# STM32MP21_CM33 register map
File version: 0.4
CPU: CM33 r0p1, little endian, MPU, FPU, vendor SysTick, 8 interrupt priority bits
Registers are 32-bit, read-write, reset 0x0 unless marked. A register's access mark holds for its fields unless they carry their own. Offsets are from the block's base; [hi:lo] are bit positions; {n}, {i} and the like mark numbered series; 'fields as' and 'values as' point back to an identical list.

## FMC (part 2 of 2) — FMC address block description
Base 0x48200000
Same registers: FMC_S 0x58200000
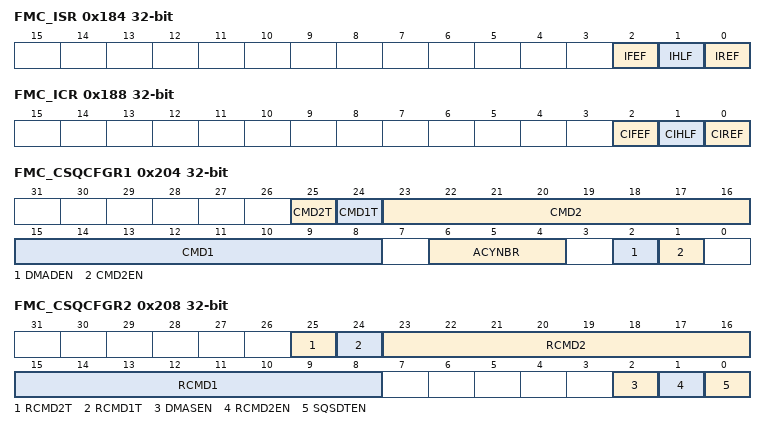
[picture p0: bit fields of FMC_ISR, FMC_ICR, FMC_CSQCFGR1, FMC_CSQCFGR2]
0x184 FMC_ISR ro — FMC interrupt status register
  [2] IFEF — Interrupt falling edge flag The flag is set by hardware and cleared by setting the CFEIF bit.
    0=No interrupt falling edge occurred; 1=Interrupt falling edge occurred
  [1] IHLF — Interrupt high-level flag The flag is set by hardware and cleared by setting the CHLIF bit.
    0=No Interrupt high-level occurred; 1=Interrupt high-level occurred
  [0] IREF — Interrupt rising edge flag The flag is set by hardware and cleared by setting the CREIF bit.
    0=No interrupt rising edge occurred; 1=Interrupt rising edge occurred
0x188 FMC_ICR wo — FMC NAND controller interrupt clear register
  [2] CIFEF — Clear Interrupt falling edge flag
    0=No effect; 1=Clears the IFEF flag in the FMC_ISR register
  [1] CIHLF — Clear Interrupt high-level flag
    0=No effect; 1=Clears the IHLF flag in the FMC_ISR register
  [0] CIREF — Clear Interrupt rising edge flag
    0=No effect; 1=Clear the IREF flag in the FMC_ISR register
0x200 FMC_CSQCR wo — FMC NAND command sequencer control register
  [0] CSQSTART — Command Sequencer Enable Writing 1 starts the Command sequencer. Writing 0 has no effect. Note: Write this bit to 1 to start the sequencer only when the FMC is enabled by setting FMCEN bit of FMC_CFGR to 1 and the NAND flash controller is activated by setting PBKEN bit of FMC_PCR to 1.
0x204 FMC_CSQCFGR1 — FMC NAND command sequencer configuration register 1
  [25] CMD2T — Command 2 Sequencer timings This bit specifies if the Command 2 (CMD2) is issued to the NAND flash memory with the timings defined in FMC_PMEM or FMC_PATT register.
    0=CMD2 issued with the timings programmed in FMC_PMEM; 1=CMD2 issued with the timings programmed in FMC_PATT
  [24] CMD1T — Command 1 Sequencer timings This bit specifies if the Command 1 (CMD1) is issued to the NAND flash memory with the timings programmed in FMC_PMEM or FMC_PATT register.
    0=CMD1 issued with the timings programmed in FMC_PMEM; 1=CMD1 issued with the timings programmed in FMC_PATT
  [23:16] CMD2 — Command 2 sequencer These bits specify if the Command 2 is issued by the command sequencer for the command second cycle during read operations.This command is only issued when the CMD2EN bit is set. Example: CMD2[7:0] bits must be programmed to 0x30 to issue the read column command.
  [15:8] CMD1 — Command 1 sequencer These bits specify if the Command 1 is issued by the command sequencer for the first cycle during read or write operations.
  [6:4] ACYNBR — Address Cycle number These bits define the number of address cycles to be generated by the command sequencer when issuing the command programmed in the registers. Others: Reserved.
    0=No address cycle; 1=1 address cycle; {v}={v} address cycles (v=2..5)
  [2] DMADEN — Command sequencer DMA request data enable When this bit is set, the command sequencer generates a DMA request to the first DMA channel, to transfer data from/to NAND flash memory.
    0=No DMA request transfer; 1=A DMA request transfer
  [1] CMD2EN — Command cycle 2 Enable This bit specifies that the command cycle 2 has to be generated by the command sequencer.
    0=Command cycle 2 not issued; 1=Command cycle 2 (programmed CMD2[7:0]) sent by the command sequencer to the NAND flash memory after the address cycles
0x208 FMC_CSQCFGR2 — FMC NAND command sequencer configuration register 2
  [25] RCMD2T — Command 1 sequencer timings This bit specifies if the CMD1 is issued to the NAND flash memory with the timings programmed in FMC_PMEM or FMC_PATT register.
    values as FMC_CSQCFGR1.CMD1T
  [24] RCMD1T — Command 1 sequencer timings This bit specifies if the CMD1 is issued to the NAND flash memory with the timings flash memory in FMC_PMEM or FMC_PATT register.
    values as FMC_CSQCFGR1.CMD1T
  [23:16] RCMD2 — Random Command 2 sequencer These bits specify that the command 2 is issued by the command sequencer for the second cycle during read operations.This command is only issued when the RCMD2EN bit is set. Example: the RCMD2 (0xE0) is required to issue the random read column command.
  [15:8] RCMD1 — Random Command 1 sequencer These bits specify that the command 1 value is issued by the command sequencer for the first cycle during read or write accesses.
  [2] DMASEN — Command sequencer DMA request decoding status enable When this bit is set, the command sequencer generates a DMA request to the second DMA channel when valid bits are available in the ECC status register at the end of ECC processing (decoding). Note: This bit must be set only during a page read sequence to offload the saving of the ECC results between sectors by using a second DMA channel.
    0=No DMA request used for ECC status registers transfer; 1=A DMA request used for ECC status registers transfer
  [1] RCMD2EN — Random Command 2 sequencer enable This bit enables the command 2 to be issued by the command sequencer during read accesses. This command is issued only when the CMD2SQEN bit is set.
    0=Command 2 not issued; 1=Command 2 (CMD2SQ[7:0]) issued by the command sequencer to NAND flash memory after the address cycle
  [0] SQSDTEN — Sequencer spare data transfer enable This bit enables the sequencer to access the spare data area after each sector transfer. It also enables the ECC when using the sequencer. ECCEN bit in FMC_PCR register must be reset.
    0=ECC disabled and spare data area not accessed by the sequencer; 1=ECC enabled and spare data area read or programmed by the sequencer after each sector transfer
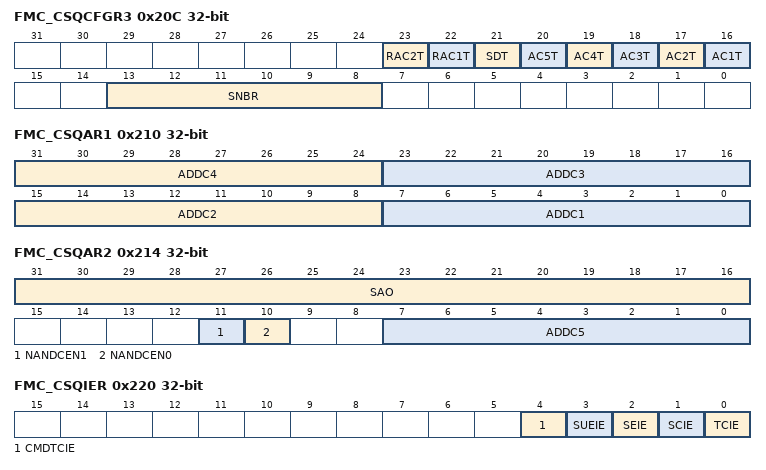
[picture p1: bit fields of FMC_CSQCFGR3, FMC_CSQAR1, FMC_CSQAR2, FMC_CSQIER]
0x20C FMC_CSQCFGR3 — FMC NAND sequencer configuration register 3
  [23] RAC2T — Random Address cycle 2 sequencer timings This bit specifies if the random Address cycle 2 (ADDC2) is issued to the NAND flash memory with the timings programmed in FMC_PMEM or in FMC_PATT register.
    0=Random ADDC2 issued with the timings programmed in FMC_PMEM; 1=Random ADDC2 issued with the timings programmed in FMC_PATT
  [22] RAC1T — Random Address cycle 1 sequencer timings This bit specifies if the random Address cycle 1 (ADDC1) is issued to the NAND flash memory with the timings programmed in FMC_PMEM or in FMC_PATT register.
    0=Random ADDC1 issued with the timings programmed in FMC_PMEM; 1=Random ADDC1 issued with the timings programmed in FMC_PATT
  [21] SDT — Spare data transfer sequencer timings This bit specifies if the spare data transfer for read and write operations from/to the NAND flash memory are performed with the timings programmed in FMC_PMEM or FMC_PATT register.
    0=Spare data transfer issued with the timings programmed in FMC_PMEM; 1=Spare data transfer issued with the timings programmed in FMC_PATT
  [20] AC5T — Address cycle 5 sequencer timings This bit defines if the Address cycle 5(ADDC1) is issued to the NAND flash memory with the timings programmed in FMC_PMEM or FMC_PATT register.
    0=ADDC5 issued with the timings programmed in FMC_PMEM; 1=ADDC5 issued with the timings programmed in FMC_PATT
  [19] AC4T — Address cycle 4sequencer timings This bit defines if the Address cycle 4 (ADDC4) is issued to the NAND flash memory with the timings programmed in FMC_PMEM or FMC_PATT register.
    0=ADDC4 issued with the timings programmed in FMC_PMEM; 1=ADDC4 issued with the timings programmed in FMC_PATT
  [18] AC3T — Address cycle 3 sequencer timings This bit defines if the Address cycle 3 (ADDC3) is issued to the NAND flash memory with the timings programmed in FMC_PMEM or FMC_PATT register.
    0=ADDC3 issued with the timings programmed in FMC_PMEM; 1=ADDC3 issued with the timings programmed in FMC_PATT
  [17] AC2T — Address cycle 2 sequencer timings This bit defines if the Address cycle 2 (ADDC2) is issued to the NAND flash memory with the timings programmed in FMC_PMEM or FMC_PATT register.
    0=ADDC2 issued with the timings programmed in FMC_PMEM; 1=ADDC2 issued with the timings programmed in FMC_PATT
  [16] AC1T — Address cycle 1 sequencer timings This bit defines if the Address cycle 1 (ADDC1) is issued to the NAND flash memory with the timings programmed in FMC_PMEM or FMC_PATT register.
    0=ADDC1 issued with the timings programmed in FMC_PMEM; 1=ADDC1 issued with the timings programmed in FMC_PATT
  [13:8] SNBR — Number of sectors to be read/written These bits define the number of sectors that are processed by the sequencer. They are used to read/write part of a page or to use the ECC (in particular with the BCH code which requires 512-byte sectors): ... Others: Reserved.
    0=1 sector; 1=2 sectors; 63=16 sectors
0x210 FMC_CSQAR1 — FMC NAND command sequencer address register 1
  [31:24] ADDC4 — Address Cycle 4 These bits define the value of address cycle 4 to be issued by the command sequencer during read or write accesses.
  [23:16] ADDC3 — Address Cycle 3 These bits define the value of address cycle 2 to be issued by the command sequencer during read or write accesses.
  [15:8] ADDC2 — Address Cycle 2 These bits define the value of address cycle 2 to be issued by the command sequencer during read or write accesses.
  [7:0] ADDC1 — Address Cycle 1 These bits define the value of address cycle 1 to be issued by the command sequencer during read or write accesses.
0x214 FMC_CSQAR2 — FMC NAND command sequencer address register 2
  [31:16] SAO — Spare Area Address Offset These bits define the offset of the first ECC byte in the spare area for the program sequence. Note: The minimum SAQ value is 2 since the first two bytes of the spare area are reserved for Bad block marking and metadata.
  [11] NANDCEN1 — NAND flash chip enable number These bits define the chip enable to be selected by the NAND flash command sequencer.
    0=NCE1 chip enable selected; 1=NCE2 chip enable selected
  [10] NANDCEN0 — NAND flash chip enable number These bits define the chip enable to be selected by the NAND flash command sequencer.
    0=NCE1 chip enable selected; 1=NCE2 chip enable selected
  [7:0] ADDC5 — Address Cycle 5 These bits define the value of address cycle 5 to be issued by the command sequencer during read or write accesses.
0x220 FMC_CSQIER — FMC NAND command sequencer interrupt enable register
  [4] CMDTCIE — Command Transfer Complete interrupt enable
    0=Command Transfer Complete Interrupt disable; 1=Command Transfer Complete Interrupt enable
  [3] SUEIE — Sector Uncorrectable Error interrupt enable
    values as CMDTCIE
  [2] SEIE — Sector Error interrupt enable
    0=Sector Error Interrupt disable; 1=Sector Error Interrupt enable
  [1] SCIE — Sector Complete interrupt enable
    0=Sector Complete Interrupt disable; 1=Sector Complete Interrupt enable
  [0] TCIE — Transfer Complete Interrupt enable
    0=Transfer Complete Interrupt disable; 1=Transfer Complete Interrupt enable
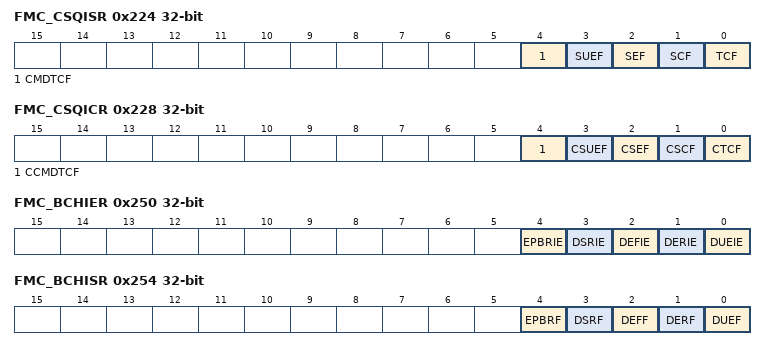
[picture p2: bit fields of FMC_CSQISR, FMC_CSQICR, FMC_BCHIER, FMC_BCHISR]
0x224 FMC_CSQISR — FMC NAND command sequencer interrupt status register
  [4] CMDTCF — Command Transfer Complete flag This bit is set when the command sequencer has completed the transfer of programmed commands and addresses. This bit is cleared by setting CCMDTCF bit. An interrupt can be generated if the CMDTCIE bit is set in the FMC_CSQICR register. Note: The Sector Transfer Complete interrupt is not needed in sequencer mode.
  [3] SUEF — Sector Uncorrectable Error flag This bit is set by hardware and cleared by writing 1 to the CSUEF bit in FMC_CSQICR. When this bit is set, it indicates that the command sequencer detected an uncorrectable error when decoding a sector. An interrupt can be generated if the SUEIE bit is set in the FMC_CSQICR register. Note: The SUEF bit is relevant only for BCH code to indicate uncorrectable errors. It must be ignored for Hamming code.
  [2] SEF — Sector Error flag This bit is set by hardware and cleared by writing 1 to the CSEF bit in FMC_CSQICR. This bit is set when the command sequencer has completed the sector data transfer with at least one error detection. An interrupt can be generated if the SEIE bit is set in the FMC_CSQICR register. Note: The SEF bit is relevant only for BCH code to indicate that errors are present. It must be ignored for Hamming code.
  [1] SCF — Sector Complete flag This bit is set by hardware and cleared by writing 1 to the CSCF bit in FMC_CSQICR. This bit is set when the command sequencer has completed the sector data transfer. An interrupt can be generated if the SCIE bit is set in the FMC_CSQICR register.
  [0] TCF — Transfer Complete flag This bit is set by hardware and cleared by writing 1 to the CTCF bit in FMC_CSQICR. This bit is set when the command sequencer has transferred all the data for all sectors or when the command sequencer was aborted. An interrupt can be generated if the TCIE bit is set in the FMC_CSQICR register.
0x228 FMC_CSQICR wo — FMC NAND command sequencer interrupt clear register
  [4] CCMDTCF — Clear Command Transfer Complete flag Writing one clears the CMTCF flag in the FMC_CSQISR register
  [3] CSUEF — Clear Sector uncorrectable Error flag Writing one clears the SUEF flag in the FMC_CSQISR register
  [2] CSEF — Clear Sector Error flag Writing one clears the SEF flag in the FMC_CSQISR register
  [1] CSCF — Clear Sector Complete flag Writing one clears the SCF flag in the FMC_CSQISR register
  [0] CTCF — Clear Transfer Complete flag Writing one clears the TCF flag in the FMC_CSQISR register
0x230 FMC_CSQEMSR ro — FMC command sequencer error mapping status register
  [15:0] SEM — Sector Error mapping When SEM[i] bit (0 less than or eqaul i less than or eqaul 15) is set, at least one error has been detected on sector i+1. As an example, SEM[2] and SEM[1] bits are set when errors are detected in sector 3 and 2.
0x250 FMC_BCHIER — FMC BCH interrupt enable register
  [4] EPBRIE — Decoder Parity Bits Ready Interrupt enable
    0=Decoder Parity Bits Ready Interrupt disable; 1=Decoder Parity Bits Ready Interrupt enable
  [3] DSRIE — Decoder Syndrome Ready Interrupt enable
    0=Decoder Syndrome Ready Interrupt disable; 1=Decoder Syndrome Ready Interrupt enable
  [2] DEFIE — Decoder Error Found Interrupt enable
    0=Decoder Error Found Interrupt disable; 1=Decoder Error Found Interrupt enable
  [1] DERIE — Decoder Error Ready Interrupt enable
    0=Decoder Error Ready Interrupt disable; 1=Decoder Error Ready Interrupt enable
  [0] DUEIE — Decoder Uncorrectable Errors Interrupt enable
    0=Decoder Uncorrectable Errors Interrupt disable; 1=Decoder Uncorrectable Errors Interrupt enable
0x254 FMC_BCHISR ro — FMC BCH interrupt and status register
  [4] EPBRF — Encoder Parity Bits Ready flag This bit is set when the BCH encoder parity bits are available in FMC_BCHPBR1 to 4.
  [3] DSRF — Decoder Syndrome Ready flag This bit is set when the syndrome is ready and DEFF is a valid field.
  [2] DEFF — Decoder Error Found flag This bit is set by hardware and cleared by writing 1 to CDEFF. This bit indicates that at least one error has been detected in the sector.
  [1] DERF — Decoder Error Ready flag This bit indicates that the decoder has finished searching errors and identifying their location. The number of errors and their location are available in FMC_BCHDSR0 and FMC_BCHDSR1 to 4, respectively.
  [0] DUEF — Decoder Uncorrectable Errors flag This field indicates that too many errors have been detected in the sector during the BCH decoding and that the sector is uncorrectable.
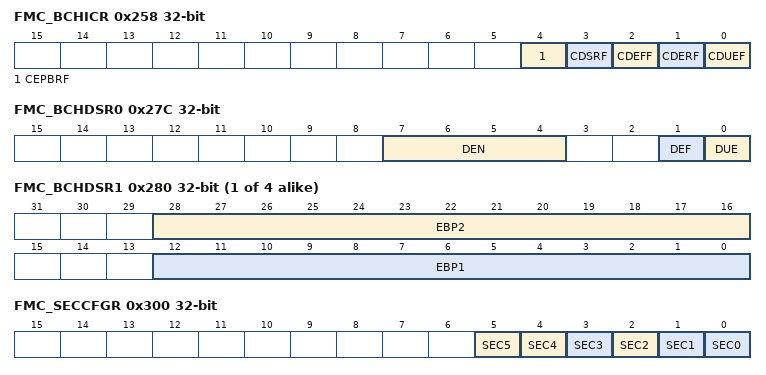
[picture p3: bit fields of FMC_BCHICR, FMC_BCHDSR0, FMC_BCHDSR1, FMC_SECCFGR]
0x258 FMC_BCHICR wo — FMC BCH interrupt clear register
  [4] CEPBRF — Clear Encoder Parity Bits Ready flag Writing 1 clears the EPBRF flag in FMC_BCHISR.
  [3] CDSRF — Clear Decoder Syndrome Ready flag Writing 1 clears the DSRF flag in FMC_BCHISR.
  [2] CDEFF — Clear Decoder Error Found flag Writing 1 clears the DEFF flag in FMC_BCHISR.
  [1] CDERF — Clear Decoder Error ready flag Writing 1 clears the DERF flag in FMC_BCHISR.
  [0] CDUEF — Clear Decoder Uncorrectable Error flag Writing 1 clears the DUEF flag in FMC_BCHISR.
{0x25C+4i} FMC_BCHPBR{i} ro (i=1..3) — FMC BCH parity bits register {i}
  [31:0] BCHPB — BCH parity bits
0x26C FMC_BCHPBR4 ro — FMC BCH parity bits register 4
  [7:0] BCHPB — BCH parity bits
0x27C FMC_BCHDSR0 ro — FMC BCH decoder status register 0
  [7:4] DEN — Decoder error number When DEF bit is set, this field indicates the number of errors detected by the BCH decoder. Following the selected BCH code, if the number of detected errors exceeds the number of correctable errors, this bit is not significant and DUE bit is set. If the BCH decoder detects a number of errors that exceeds the maximum number of detectable errors, DEN is not significant.
  [1] DEF — Decoder error found This field indicates that the decoder has finished searching errors and identifying their location. The number of errors and their location are available in FMC_BCHDSR0 and FMC_BCHDSR1 to 4, respectively.
  [0] DUE — Decoder uncorrectable error This field indicates that too many errors have been detected in the sector during the BCH decoding and that the sector is uncorrectable. If the BCH decoder detects a number of errors that exceeds the maximum number of detectable errors, DUE is not significant.
{0x27C+4i} FMC_BCHDSR{i} ro (i=1..4) — FMC BCH decoder status register for memory region {i}
  [28:16] EBP{2i} — Error bit position for error number {2i}
  [12:0] EBP{2i-1} — Error bit position for error number {2i-1}
0x300 FMC_SECCFGR — FMC security configuration register
  [all] fields
    0=non-secure; 1=secure
  [5] SEC5 — Security configuration for NAND controller
  [n] SEC{n} (n=1..4) — Security state for NOR/PSRAM controller for Chip Select NE{n}
  [0] SEC0 — Security state for FMC_CFGR common control register
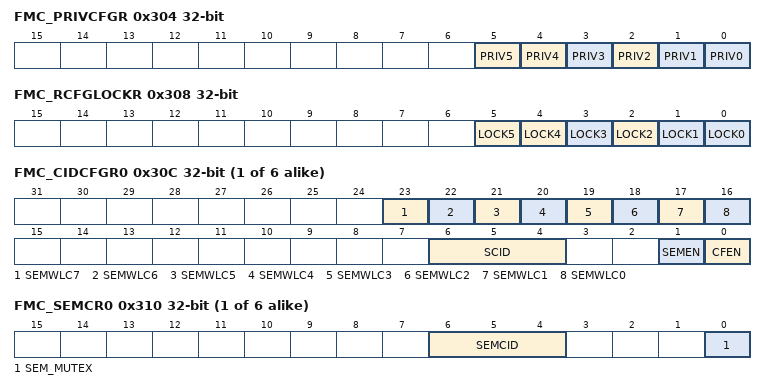
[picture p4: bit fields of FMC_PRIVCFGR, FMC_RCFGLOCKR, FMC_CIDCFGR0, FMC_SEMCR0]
0x304 FMC_PRIVCFGR — FMC security configuration register
  [all] fields
    0=unprivileged; 1=privileged
  [5] PRIV5 — Privileged state for NAND controller
  [n] PRIV{n} (n=1..4) — Privileged state for NOR/PSRAM controller for Chip Select NE{n}
  [0] PRIV0 — Privileged state for common control: FMC_CFGR
0x308 FMC_RCFGLOCKR — FMC CID configuration lock register
  [5] LOCK5 — Lock NAND controller until a global FMC reset
    0=no effect; 1=FMC_CIDCFGR5, SEC[5] of FMC_SECCFGR and FMC_PRIVCFGR[5] are write locked
  [n] LOCK{n} (n=1..4) — Lock NOR/PSRAM controller for Chip Select NE{n} until a global FMC reset
    0=no effect; 1=FMC_CIDCFGR{n}, SEC[{n}] of FMC_SECCFGR and FMC_PRIVCFGR[{n}] are write locked
  [0] LOCK0 — Lock FMC_CFGR until a global FMC reset
    0=no effect; 1=FMC_CIDCFGR0, SEC[0] of FMC_SECCFGR and FMC_PRIVCFGR[0] are write locked
{0x30C+8i} FMC_CIDCFGR{i} (i=0..5) — FMC resource {i} CID register
  [23] SEMWLC7 — White-listed CID in the CID allocation pool for resource x in semaphore mode
    0=CID7 is black-listed in CID allocation pool; 1=CID7 is white-listed in CID allocation pool
  [22] SEMWLC6 — White-listed CID0 in the CID allocation pool for resource x in semaphore mode
    0=CID6 is black-listed in CID allocation pool; 1=CID6 is white-listed in CID allocation pool
  [21] SEMWLC5 — White-listed CID0 in the CID allocation pool of resource x in semaphore mode
    0=CID5 is black-listed in CID allocation pool; 1=CID5 is white-listed in CID allocation pool
  [20] SEMWLC4 — White-listed CID0 in the CID allocation pool of resource x in semaphore mode
    0=CID4 is black-listed in CID allocation pool; 1=CID4 is white-listed in CID allocation pool
  [19] SEMWLC3 — White-listed CID in the CID allocation pool of resource x in semaphore mode
    0=CID3 is black-listed in CID allocation pool; 1=CID3 is white-listed in CID allocation pool
  [18] SEMWLC2 — White-listed CID in the CID allocation pool of resource x in semaphore mode
    0=CID2 is black-listed in CID allocation pool; 1=CID2 is white-listed in CID allocation pool
  [17] SEMWLC1 — White-listed CID0 in the CID allocation pool of resource x in semaphore mode
    0=CID1 is black-listed in CID allocation pool; 1=CID1 is white-listed in CID allocation pool
  [16] SEMWLC0 — White-listed CID0 in the CID allocation pool of resource x in semaphore mode
    0=CID0 is black-listed in CID allocation pool; 1=CID0 is white-listed in CID allocation pool
  [6:4] SCID — Static CID for resource x Trusted domain applications use this bit to statically define which compartment has access to the resource x when SEMEN=0. This bit is ignored if SEMEN=1 or CFEN=0.
  [1] SEMEN — Semaphore enable for resource x
    0=disable the semaphore mode; 1=enable the semaphore mode
  [0] CFEN — CID filtering enable for resource x
    0=disable CID filtering; 1=enable CID filtering
{0x310+8i} FMC_SEMCR{i} (i=0..5) — FMC resource {i} semaphore control register
  [6:4] SEMCID ro — Current CID allocated to resource x in semaphore mode The field is read-only. It is internally updated when a white-listed CID has taken the control of resource x, in semaphore mode. If SEM_MUTEX=0, this CID also released it.
  [0] SEM_MUTEX — Mutex for the CID allocation of resource x in semaphore mode Write access: Write 0: Control of resource x (in semaphore mode) released to any white-listed CID Write 1: Control of resource x (in semaphore mode) acquired by a white-listed CID Read access: Read 0: Resource x is CID-free, meaning that it is not (currently) under the control of any white-listed CID Read 1: Resource x is CID-allocated, meaning that it is (currently) under the control of one white-listed CID If resource x is in secure state (SECx=1 in FMC_SECCFGR), this bit can be written only by a secure agent. If resource x is in privileged state (FMC_PRIVCFGR.PRIVx=1), this bit can be written only by a privileged agent. If resource x is CID-filtered (CFEN=1 in FMC_CIDCFGRx) and in semaphore mode (FMC_CIDCFGR.SEMEN=1), this bit can be written either by an authorized (white-listed) CID agent to acquire the control or by the same (white-listed) CID agent to release the control.
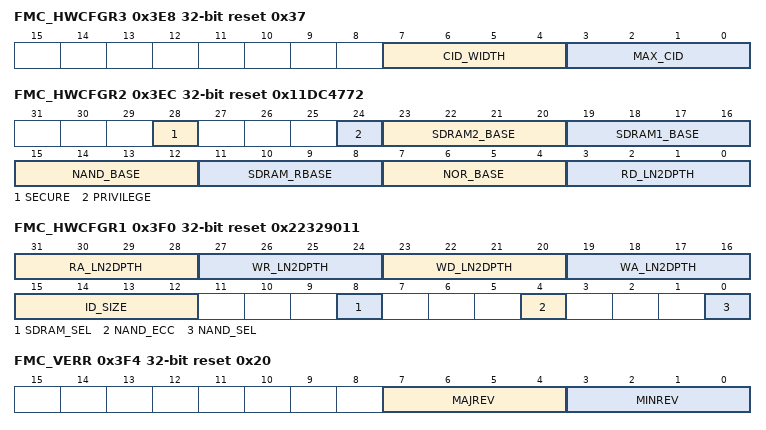
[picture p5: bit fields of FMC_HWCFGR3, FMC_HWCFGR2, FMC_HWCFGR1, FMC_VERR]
0x3E8 FMC_HWCFGR3 ro reset 0x37 — FMC hardware configuration register 3
  [7:4] CID_WIDTH — CID bus width This bit field is relevant only when MAX_CID is not null in FMC_HWCFGR2. Others: Reserved, must not be used.
    {v}=Width = {v+1} (v=0..3)
  [3:0] MAX_CID — Maximum compartment ID (or CID) MAX_CID ranges from 0 to 15: 0001 to 1111: FMC is CID-aware and each channel is a separate CID-aware resource. n+1 CIDs, from CID0 up to CIDn, are supported.
    0=no CID supported, DMA is not CID-aware
0x3EC FMC_HWCFGR2 ro reset 0x11DC4772 — FMC hardware configuration register 2
  [28] SECURE — Support for Armsupsuperior /supsuperior TrustZonesupsuperior /supsuperior Note: Arm and TrustZone are registered trademarks of Arm Limited (or its subsidiaries) in the US and/or elsewhere
    0=no TrustZone; 1=Support for TrustZone
  [24] PRIVILEGE — Support for Privileged mode
    0=Privileged mode not supported; 1=Privileged mode supported
  [23:20] SDRAM2_BASE — SDRAM bank 2 base address It returns bits [31:28] of SDRAM bank 2 base address space when the SDRAM controller is supported. It is ignored otherwise.
  [19:16] SDRAM1_BASE — SDRAM bank 1 base address It returns bits [31:28] of SDRAM bank 1 base address space when the SDRAM controller is supported. It is ignored otherwise.
  [15:12] NAND_BASE — NAND base address It returns bits [31:28] of NAND base address space
  [11:8] SDRAM_RBASE — SDRAM remap base address it returns bits [31:28] of SDRAM remap base address space when the SDRAM controller is supported. It is ignored otherwise.
  [7:4] NOR_BASE — NOR base address It returns bits [31:28] of NOR base address space
  [3:0] RD_LN2DPTH — AXI read data FIFO depth These bits return the AXI read data FIFO depth. depth is 2supsuperiorRD_LN2DPTH/supsuperior
0x3F0 FMC_HWCFGR1 ro reset 0x22329011 — FMC hardware configuration register 1
  [31:28] RA_LN2DPTH — AXI read address FIFO depth These bits return the AXI read address FIFO depth. depth is 2supsuperiorRA_LN2DPTH/supsuperior.
  [27:24] WR_LN2DPTH — AXI write response FIFO depth These bits return the AXI write response FIFO depth. depth is 2supsuperiorWR_LN2DPTH/supsuperior.
  [23:20] WD_LN2DPTH — AXI write data FIFO depth These bits return the AXI write data FIFO depth. depth is 2supsuperiorWD_LN2DPTH/supsuperior.
  [19:16] WA_LN2DPTH — AXI write address FIFO depth These bits return the AXI write address FIFO depth. depth is 2supsuperiorWA_LN2DPTH/supsuperior.
  [15:12] ID_SIZE — AXI ID width These bits return the AXI ID width.
  [8] SDRAM_SEL — SDRAM controller selection
    0=SDRAM controller not supported; 1=SDRAM controller supported
  [4] NAND_ECC
    0=Hamming code (supported only in Legacy mode without sequencer); 1=Hamming and BCH code
  [0] NAND_SEL — NAND Controller Selection
    0=NAND Controller not supported; 1=NAND Controller supported
0x3F4 FMC_VERR ro reset 0x20 — FMC version register
  [7:4] MAJREV — Major revision These bits return the FMC major revision
  [3:0] MINREV — Minor revision These bits return the FMC minor revision
0x3F8 FMC_IPIDR ro reset 0x140002 — FMC identification register
  [31:0] ID — FMC Identifier These bits return the FMC identifier
0x3FC FMC_SIDR ro reset 0xA3C5DD01 — FMC size identification register
  [31:0] SID — Size Identification These bits return the size of the memory region allocated to the FMC registers.
